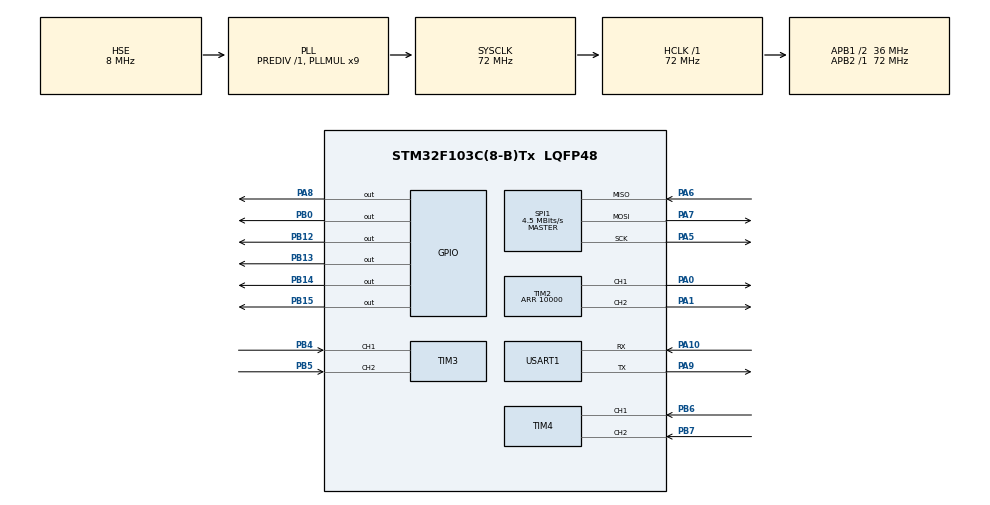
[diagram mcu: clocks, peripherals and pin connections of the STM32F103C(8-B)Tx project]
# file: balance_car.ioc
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Dma.Request0=SPI1_RX
Dma.Request1=SPI1_TX
Dma.Request2=USART1_TX
Dma.SPI1_RX.0.Direction=DMA_PERIPH_TO_MEMORY
Dma.SPI1_RX.0.Instance=DMA1_Channel2
Dma.SPI1_RX.0.MemDataAlignment=DMA_MDATAALIGN_BYTE
Dma.SPI1_RX.0.MemInc=DMA_MINC_ENABLE
Dma.SPI1_RX.0.Mode=DMA_NORMAL
Dma.SPI1_RX.0.PeriphDataAlignment=DMA_PDATAALIGN_BYTE
Dma.SPI1_RX.0.PeriphInc=DMA_PINC_DISABLE
Dma.SPI1_RX.0.Priority=DMA_PRIORITY_LOW
Dma.SPI1_TX.1.Direction=DMA_MEMORY_TO_PERIPH
Dma.SPI1_TX.1.Instance=DMA1_Channel3
Dma.SPI1_TX.1.MemDataAlignment=DMA_MDATAALIGN_BYTE
Dma.SPI1_TX.1.MemInc=DMA_MINC_ENABLE
Dma.SPI1_TX.1.Mode=DMA_NORMAL
Dma.SPI1_TX.1.PeriphDataAlignment=DMA_PDATAALIGN_BYTE
Dma.SPI1_TX.1.PeriphInc=DMA_PINC_DISABLE
Dma.SPI1_TX.1.Priority=DMA_PRIORITY_LOW
Dma.USART1_TX.2.Direction=DMA_MEMORY_TO_PERIPH
Dma.USART1_TX.2.Instance=DMA1_Channel4
Dma.USART1_TX.2.MemDataAlignment=DMA_MDATAALIGN_BYTE
Dma.USART1_TX.2.MemInc=DMA_MINC_ENABLE
Dma.USART1_TX.2.Mode=DMA_NORMAL
Dma.USART1_TX.2.PeriphDataAlignment=DMA_PDATAALIGN_BYTE
Dma.USART1_TX.2.PeriphInc=DMA_PINC_DISABLE
Dma.USART1_TX.2.Priority=DMA_PRIORITY_LOW
Mcu.Family=STM32F1
Mcu.Name=STM32F103C(8-B)Tx
Mcu.Package=LQFP48
NVIC.DMA1_Channel2_IRQn=true\:0\:0\:false\:false\:true\:false\:true\:true
NVIC.DMA1_Channel3_IRQn=true\:0\:0\:false\:false\:true\:false\:true\:true
NVIC.DMA1_Channel4_IRQn=true\:0\:0\:false\:false\:true\:false\:true\:true
NVIC.PriorityGroup=NVIC_PRIORITYGROUP_4
NVIC.USART1_IRQn=true\:0\:0\:false\:false\:true\:false\:true\:true
PA0-WKUP.Signal=S_TIM2_CH1_ETR
PA1.Signal=S_TIM2_CH2
PA10.Mode=Asynchronous
PA10.Signal=USART1_RX
PA13.Mode=Serial_Wire
PA13.Signal=SYS_JTMS-SWDIO
PA14.Mode=Serial_Wire
PA14.Signal=SYS_JTCK-SWCLK
PA5.Mode=Full_Duplex_Master
PA5.Signal=SPI1_SCK
PA6.Mode=Full_Duplex_Master
PA6.Signal=SPI1_MISO
PA7.Mode=Full_Duplex_Master
PA7.Signal=SPI1_MOSI
PA8.GPIO_Speed=GPIO_SPEED_FREQ_HIGH
PA8.Signal=GPIO_Output
PA9.Mode=Asynchronous
PA9.Signal=USART1_TX
PB0.Signal=GPIO_Output
PB12.GPIO_Speed=GPIO_SPEED_FREQ_HIGH
PB12.Signal=GPIO_Output
PB13.GPIO_Speed=GPIO_SPEED_FREQ_HIGH
PB13.Signal=GPIO_Output
PB14.GPIO_Speed=GPIO_SPEED_FREQ_HIGH
PB14.Signal=GPIO_Output
PB15.Signal=GPIO_Output
PB4.Signal=S_TIM3_CH1
PB5.Signal=S_TIM3_CH2
PB6.Signal=S_TIM4_CH1
PB7.Signal=S_TIM4_CH2
PD0-OSC_IN.Mode=HSE-External-Oscillator
PD0-OSC_IN.Signal=RCC_OSC_IN
PD1-OSC_OUT.Mode=HSE-External-Oscillator
PD1-OSC_OUT.Signal=RCC_OSC_OUT
ProjectManager.HeapSize=0x200
ProjectManager.StackSize=0x400
ProjectManager.TargetToolchain=CMake
RCC.AHBFreq_Value=72000000
RCC.APB1CLKDivider=RCC_HCLK_DIV2
RCC.APB1Freq_Value=36000000
RCC.APB1TimFreq_Value=72000000
RCC.APB2Freq_Value=72000000
RCC.APB2TimFreq_Value=72000000
RCC.HCLKFreq_Value=72000000
RCC.PLLMUL=RCC_PLL_MUL9
RCC.PLLSourceVirtual=RCC_PLLSOURCE_HSE
RCC.SYSCLKFreq_VALUE=72000000
RCC.SYSCLKSource=RCC_SYSCLKSOURCE_PLLCLK
RCC.USBFreq_Value=72000000
SH.S_TIM2_CH1_ETR.0=TIM2_CH1,PWM Generation1 CH1
SH.S_TIM2_CH2.0=TIM2_CH2,PWM Generation2 CH2
SH.S_TIM3_CH1.0=TIM3_CH1,Encoder_Interface
SH.S_TIM3_CH2.0=TIM3_CH2,Encoder_Interface
SH.S_TIM4_CH1.0=TIM4_CH1,Encoder_Interface
SH.S_TIM4_CH2.0=TIM4_CH2,Encoder_Interface
SPI1.BaudRatePrescaler=SPI_BAUDRATEPRESCALER_16
SPI1.CalculateBaudRate=4.5 MBits/s
SPI1.Direction=SPI_DIRECTION_2LINES
SPI1.Mode=SPI_MODE_MASTER
SPI1.VirtualType=VM_MASTER
TIM1.Prescaler=72-1
TIM2.Channel-PWM\ Generation1\ CH1=TIM_CHANNEL_1
TIM2.Channel-PWM\ Generation2\ CH2=TIM_CHANNEL_2
TIM2.Period=10000
TIM3.EncoderMode=TIM_ENCODERMODE_TI12
TIM4.EncoderMode=TIM_ENCODERMODE_TI12
USART1.VirtualMode=VM_ASYNC
VP_TIM1_VS_ClockSourceINT.Mode=Internal
board=custom

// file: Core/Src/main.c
/* USER CODE BEGIN Header */
/**
  ******************************************************************************
  * @file           : main.c
  * @brief          : 主程序文件
  ******************************************************************************
  * @attention
  *
  * Copyright (c) 2026 STMicroelectronics.
  * All rights reserved.
  *
  * This software is licensed under terms that can be found in the LICENSE file
  * in the root directory of this software component.
  * If no LICENSE file comes with this software, it is provided AS-IS.
  *
  ******************************************************************************
  */
/* USER CODE END Header */
#include "main.h"
#include "dma.h"
#include "spi.h"
#include "tim.h"
#include "usart.h"
#include "gpio.h"

/* USER CODE BEGIN Includes */
#include "balance_system.h"
#include "get_target.h"
/* USER CODE END Includes */

/* USER CODE BEGIN PTD */
static uint8_t is_error = 0; // 错误标志
static Balance_Target_t target; // 平衡控制的目标状态

/* USER CODE END PTD */

void SystemClock_Config(void);

int main(void)
{

  /* MCU Configuration--------------------------------------------------------*/

  /* Reset of all peripherals, Initializes the Flash interface and the Systick. */
      HAL_Init();

  /* Configure the system clock */
  SystemClock_Config();

  /* Initialize all configured peripherals */
  MX_GPIO_Init();
  MX_DMA_Init();
  MX_SPI1_Init();
  MX_TIM1_Init();
  MX_USART1_UART_Init();
  MX_TIM2_Init();
  MX_TIM3_Init();
  MX_TIM4_Init();
  /* USER CODE BEGIN 2 */
  HAL_TIM_Base_Start(&htim1);

  balance_system_init(); // 初始化平衡系统，包括姿态、底盘和控制器的初始化
  //获取定时器tim1的当前计数值，作为上次更新的系统时钟滴答数
  uint8_t first_update = 1; // 是否是第一次更新的标志

  while (1)
  {
    /* USER CODE END WHILE */
    get_new_target(&target); // 获取新的目标状态
    balance_system_run(target, &is_error, &first_update); // 运行平衡系统，传入目标状态、错误标志和第一次更新标志
  }
}

void SystemClock_Config(void)
{
  RCC_OscInitTypeDef RCC_OscInitStruct = {0};
  RCC_ClkInitTypeDef RCC_ClkInitStruct = {0};

  /** Initializes the RCC Oscillators according to the specified parameters
  * in the RCC_OscInitTypeDef structure.
  */
  RCC_OscInitStruct.OscillatorType = RCC_OSCILLATORTYPE_HSE;
  RCC_OscInitStruct.HSEState = RCC_HSE_ON;
  RCC_OscInitStruct.HSEPredivValue = RCC_HSE_PREDIV_DIV1;
  RCC_OscInitStruct.HSIState = RCC_HSI_ON;
  RCC_OscInitStruct.PLL.PLLState = RCC_PLL_ON;
  RCC_OscInitStruct.PLL.PLLSource = RCC_PLLSOURCE_HSE;
  RCC_OscInitStruct.PLL.PLLMUL = RCC_PLL_MUL9;
  if (HAL_RCC_OscConfig(&RCC_OscInitStruct) != HAL_OK)
  {
    Error_Handler();
  }

  /** Initializes the CPU, AHB and APB buses clocks
  */
  RCC_ClkInitStruct.ClockType = RCC_CLOCKTYPE_HCLK|RCC_CLOCKTYPE_SYSCLK
                              |RCC_CLOCKTYPE_PCLK1|RCC_CLOCKTYPE_PCLK2;
  RCC_ClkInitStruct.SYSCLKSource = RCC_SYSCLKSOURCE_PLLCLK;
  RCC_ClkInitStruct.AHBCLKDivider = RCC_SYSCLK_DIV1;
  RCC_ClkInitStruct.APB1CLKDivider = RCC_HCLK_DIV2;
  RCC_ClkInitStruct.APB2CLKDivider = RCC_HCLK_DIV1;

  if (HAL_RCC_ClockConfig(&RCC_ClkInitStruct, FLASH_LATENCY_2) != HAL_OK)
  {
    Error_Handler();
  }
}

void Error_Handler(void)
{
  __disable_irq();
  while (1)
  {
  }
}
